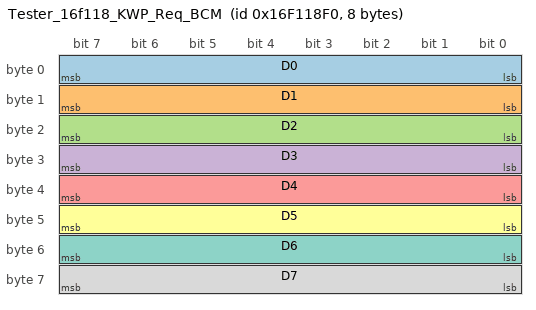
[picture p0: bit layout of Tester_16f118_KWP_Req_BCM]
BO_ 384899312 Tester_16f118_KWP_Req_BCM: 8 XXX
 SG_ D0 : 7|8@0+ (1,0) [0|0] "" XXX
 SG_ D1 : 15|8@0+ (1,0) [0|0] "" XXX
 SG_ D2 : 23|8@0+ (1,0) [0|0] "" XXX
 SG_ D3 : 31|8@0+ (1,0) [0|0] "" XXX
 SG_ D4 : 39|8@0+ (1,0) [0|0] "" XXX
 SG_ D5 : 47|8@0+ (1,0) [0|0] "" XXX
 SG_ D6 : 55|8@0+ (1,0) [0|0] "" XXX
 SG_ D7 : 63|8@0+ (1,0) [0|0] "" XXX
